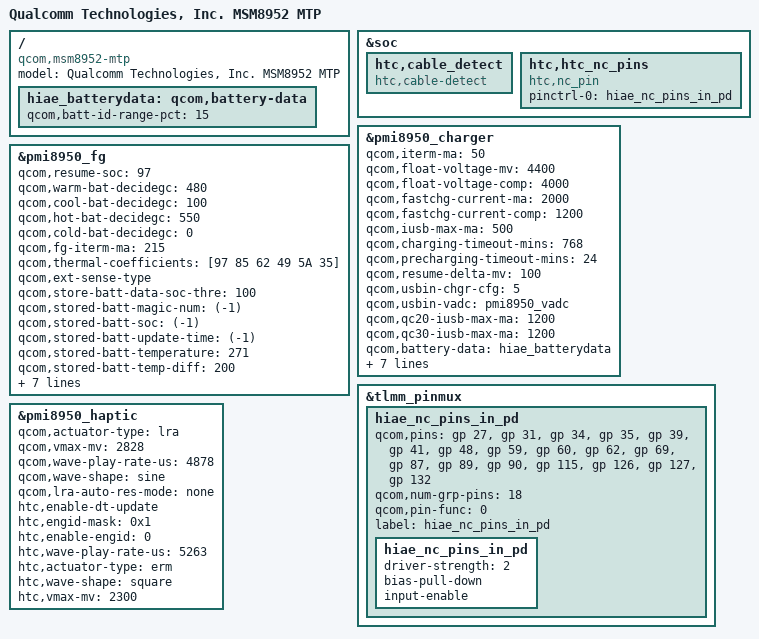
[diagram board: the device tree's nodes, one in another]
/*
 * Copyright (c) 2015, The Linux Foundation. All rights reserved.
 *
 * This program is free software; you can redistribute it and/or modify
 * it under the terms of the GNU General Public License version 2 and
 * only version 2 as published by the Free Software Foundation.
 *
 * This program is distributed in the hope that it will be useful,
 * but WITHOUT ANY WARRANTY; without even the implied warranty of
 * MERCHANTABILITY or FITNESS FOR A PARTICULAR PURPOSE.  See the
 * GNU General Public License for more details.
 */

#include "msm8952-mtp.dtsi"
#include "msm8952-htc-common.dtsi"
#include "msm8952-htc-ramdumpheap.dtsi"
#include "msm8952-key-hima_aero.dtsi"

/ {
	model = "Qualcomm Technologies, Inc. MSM8952 MTP";
	compatible = "qcom,msm8952-mtp", "qcom,msm8952", "qcom,mtp";
};
/*++ 2015/5/26 USB Team, PCN00010 ++*/
&soc {
	htc,cable_detect {
	compatible = "htc,cable-detect";
	};

	htc,htc_nc_pins {
		compatible = "htc,nc_pin";

		pinctrl-names = "default";
		pinctrl-0 = <&hiae_nc_pins_in_pd>;
	};
};
/*-- 2015/5/26 USB Team, PCN00010 --*/

&pmi8950_charger {
	qcom,iterm-ma = <50>;
	qcom,float-voltage-mv = <4400>;
	qcom,float-voltage-comp = <4000>;
	qcom,fastchg-current-ma = <2000>;
	qcom,fastchg-current-comp = <1200>;
	qcom,iusb-max-ma = <500>;
	qcom,charging-timeout-mins = <768>;
	qcom,precharging-timeout-mins = <24>;
	qcom,resume-delta-mv = <100>;

	qcom,usbin-chgr-cfg = <5>;
	qcom,usbin-vadc = <&pmi8950_vadc>;

	qcom,qc20-iusb-max-ma = <1200>;
	qcom,qc30-iusb-max-ma = <1200>;
	qcom,battery-data = <&hiae_batterydata>;

	htc,htc-thermal-temp-thr-qc20 = <420>;
	htc,htc-thermal-limit-iusb-cur-qc20 = <900>;

	htc,eoc-ibat-thre-ma = <215>;
	htc,adjust-fastchg-cur-thr-mv = <4340>;
	htc,cv-fastchg-cur-ma = <1500>;
	htc,otg-output-current-ma = <750>;
	htc,wa-adjust-iusb-max-to-prevent-over-chg-from-1A-adaptor;
};

&pmi8950_fg {
	qcom,resume-soc = <97>;
	qcom,warm-bat-decidegc = <480>;
	qcom,cool-bat-decidegc = <100>;
	qcom,hot-bat-decidegc = <550>;
	qcom,cold-bat-decidegc = <0>;
	qcom,fg-iterm-ma = <215>;
	qcom,thermal-coefficients = [97 85 62 49 5A 35];
	qcom,ext-sense-type;
	qcom,store-batt-data-soc-thre = <100>;
	qcom,stored-batt-magic-num = <(-1)>;
	qcom,stored-batt-soc = <(-1)>;
	qcom,stored-batt-update-time = <(-1)>;
	qcom,stored-batt-temperature = <271>;
	qcom,stored-batt-temp-diff = <200>;
	qcom,fg-chg-iterm-ma = <50>;
	qcom,fg-cutoff-voltage-mv = <3400>;
	qcom,stored-batt-total-level = <0>;
	qcom,stored-batt-overheat-sec = <0>;
	qcom,stored-batt-first-use = <0>;
	qcom,stored-batt-checksum = <0>;

	qcom,battery-data = <&hiae_batterydata>;
};

/{
	hiae_batterydata: qcom,battery-data {
		qcom,batt-id-range-pct = <15>;
		#include "batterydata-hiae-id1.dtsi"
		#include "batterydata-hiae-id2.dtsi"
		#include "batterydata-hiae-unknown.dtsi"
	};
};

&tlmm_pinmux {
	hiae_nc_pins_in_pd {
		qcom,pins = <&gp 27>, <&gp 31>, <&gp 34>, <&gp 35>, <&gp 39>, <&gp 41>, <&gp 48>,
			    <&gp 59>, <&gp 60>, <&gp 62>, <&gp 69>, <&gp 87>, <&gp 89>, <&gp 90>,
			    <&gp 115>, <&gp 126>, <&gp 127>, <&gp 132>;
		qcom,num-grp-pins = <18>;
		qcom,pin-func = <0>;
		label = "hiae_nc_pins_in_pd";
		hiae_nc_pins_in_pd: hiae_nc_pins_in_pd {
			driver-strength = <2>;	/* 2 mA */
			bias-pull-down;		/* PULL DOWN */
			input-enable;
		};
	};
};

&pmi8950_haptic {
	qcom,actuator-type = "lra";
	qcom,vmax-mv = <2828>;				/* √2*2Vrms for sine wave */
	qcom,wave-play-rate-us = <4878>;	/* for 205Hz */
	qcom,wave-shape = "sine";
	qcom,lra-auto-res-mode="none";		/* Disable auto resonance */
	htc,enable-dt-update;
	htc,engid-mask = <0x1>;
	htc,enable-engid = <0>;
	htc,wave-play-rate-us = <5263>;
	htc,actuator-type = "erm";
	htc,wave-shape = "square";
	htc,vmax-mv = <2300>;
};
